# AST1080 register map
File version: 1.0
CPU: CM4 r0p1, little endian, MPU, FPU, 4 interrupt priority bits, 256 interrupts
Registers are 32-bit, read-write, reset 0x0 unless marked. A register's access mark holds for its fields unless they carry their own. Offsets are from the block's base; [hi:lo] are bit positions; {n}, {i} and the like mark numbered series.

## otp_reg
Base 0x74C07000
0x00 OTP_REG000 — otp key
  [31:0] REGOTPENABLEID ro
0x04 OTP_REG004 — otp\_cmd\_m0
  [31:0] REGOTPCMDM0
0x08 OTP_REG008 — otp\_wdata\_m0\_0
  [31:0] REGOTPWDATAM00
0x0C OTP_REG00C — otp\_wdata\_m0\_1
  [31:0] REGOTPWDATAM01
0x10 OTP_REG010 — otp\_wdata\_m0\_2
  [31:0] REGOTPWDATAM02
0x14 OTP_REG014 — otp\_wdata\_m0\_3
  [31:0] REGOTPWDATAM03
0x18 OTP_REG018 — otp\_states\_m0
  [31:0] REGOTPSTATUSM0 ro
0x1C OTP_REG01C — otp\_addr\_m0
  [15:0] REGOTPADDRM0
0x20 OTP_REG020 — otp\_rdata\_m0
  [31:0] REGOTPRDATAM0 ro
0x24 OTP_REG024 — otp\_cmd\_m1
  [31:0] REGOTPCMDM1
0x28 OTP_REG028 — otp\_wdata\_m1\_0
  [31:0] REGOTPWDATAM10
0x2C OTP_REG02C — otp\_wdata\_m1\_1
  [31:0] REGOTPWDATAM11
0x30 OTP_REG030 — otp\_wdata\_m1\_2
  [31:0] REGOTPWDATAM12
0x34 OTP_REG034 — otp\_wdata\_m1\_3
  [31:0] REGOTPWDATAM13
0x38 OTP_REG038 — otp\_states\_m1
  [31:0] REGOTPSTATUSM1 ro
0x3C OTP_REG03C — otp\_addr\_m1
  [15:0] REGOTPADDRM1
0x40 OTP_REG040 — otp\_rdata\_m1
  [31:0] REGOTPRDATAM1 ro
0x44 OTP_REG044 — otp\_cmd\_m2
  [31:0] REGOTPCMDM2
0x48 OTP_REG048 — otp\_wdata\_m2\_0
  [31:0] REGOTPWDATAM20
0x4C OTP_REG04C — otp\_wdata\_m2\_1
  [31:0] REGOTPWDATAM21
0x50 OTP_REG050 — otp\_wdata\_m2\_2
  [31:0] REGOTPWDATAM22
0x54 OTP_REG054 — otp\_wdata\_m2\_3
  [31:0] REGOTPWDATAM23
0x58 OTP_REG058 — otp\_states\_m2
  [31:0] REGOTPSTATUSM2 ro
0x5C OTP_REG05C — otp\_addr\_m2
  [15:0] REGOTPADDRM2
0x60 OTP_REG060 — otp\_rdata\_m2
  [31:0] REGOTPRDATAM2 ro
0x64 OTP_REG064 — otp\_cmd\_m3
  [31:0] REGOTPCMDM3
0x68 OTP_REG068 — otp\_wdata\_m3\_0
  [31:0] REGOTPWDATAM30
0x6C OTP_REG06C — otp\_wdata\_m3\_1
  [31:0] REGOTPWDATAM31
0x70 OTP_REG070 — otp\_wdata\_m3\_2
  [31:0] REGOTPWDATAM32
0x74 OTP_REG074 — otp\_wdata\_m3\_3
  [31:0] REGOTPWDATAM33
0x78 OTP_REG078 — otp\_states\_m3
  [31:0] REGOTPSTATUSM3 ro
0x7C OTP_REG07C — otp\_addr\_m3
  [15:0] REGOTPADDRM3
0x80 OTP_REG080 — otp\_rdata\_m3
  [31:0] REGOTPRDATAM3 ro
0x84 OTP_REG084 — otp\_cmd\_m4
  [31:0] REGOTPCMDM4
0x88 OTP_REG088 — otp\_wdata\_m4\_0
  [31:0] REGOTPWDATAM40
0x8C OTP_REG08C — otp\_wdata\_m4\_1
  [31:0] REGOTPWDATAM41
0x90 OTP_REG090 — otp\_wdata\_m4\_2
  [31:0] REGOTPWDATAM42
0x94 OTP_REG094 — otp\_wdata\_m4\_3
  [31:0] REGOTPWDATAM43
0x98 OTP_REG098 — otp\_states\_m4
  [31:0] REGOTPSTATUSM4 ro
0x9C OTP_REG09C — otp\_addr\_m4
  [15:0] REGOTPADDRM4
0xA0 OTP_REG0A0 — otp\_rdata\_m4
  [31:0] REGOTPRDATAM4 ro
0xA4 OTP_REG0A4 — otp\_cmd\_m5
  [31:0] REGOTPCMDM5
0xA8 OTP_REG0A8 — otp\_wdata\_m5\_0
  [31:0] REGOTPWDATAM50
0xAC OTP_REG0AC — otp\_wdata\_m5\_1
  [31:0] REGOTPWDATAM51
0xB0 OTP_REG0B0 — otp\_wdata\_m5\_2
  [31:0] REGOTPWDATAM52
0xB4 OTP_REG0B4 — otp\_wdata\_m5\_3
  [31:0] REGOTPWDATAM53
0xB8 OTP_REG0B8 — otp\_states\_m5
  [31:0] REGOTPSTATUSM5 ro
0xBC OTP_REG0BC — otp\_addr\_m5
  [15:0] REGOTPADDRM5
0xC0 OTP_REG0C0 — otp\_rdata\_m5
  [31:0] REGOTPRDATAM5 ro
0xC4 OTP_REG0C4 — otp\_dbg\_00
  [31:0] REGDBG0 ro
0xC8 OTP_REG0C8 — otp\_dbg\_01
  [31:0] REGDBG1 ro
0xCC OTP_REG0CC — ecc\_rlock
  [0] REGECCRLOCK
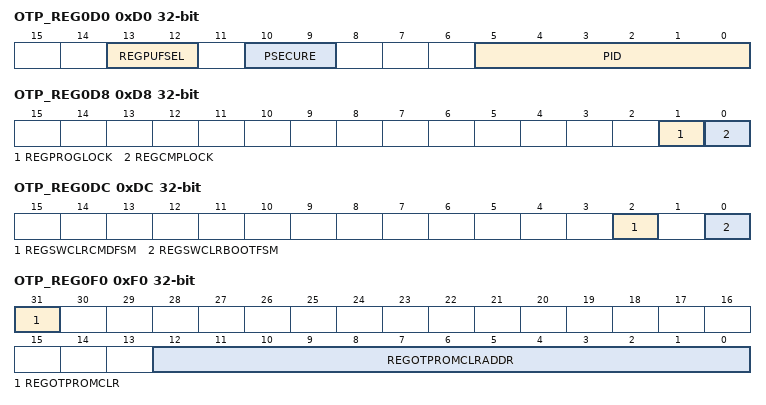
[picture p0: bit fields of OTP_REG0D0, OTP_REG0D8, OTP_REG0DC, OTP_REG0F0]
0xD0 OTP_REG0D0 — pid
  [13:12] REGPUFSEL, [10:9] PSECURE ro, [5:0] PID ro
0xD4 OTP_REG0D4 — otp\_eccbrp\_en
  [0] REGOTPECCBRPEN
0xD8 OTP_REG0D8 — OTP\_CMD\_LOCK
  [1] REGPROGLOCK, [0] REGCMPLOCK
0xDC OTP_REG0DC — otp\_sw\_reset
  [2] REGSWCLRCMDFSM, [0] REGSWCLRBOOTFSM
0xE0 OTP_REG0E0 — otp\_trng\_dbg
  [31:0] REGDBGTRNG ro
0xF0 OTP_REG0F0 — otp\_rom\_clr
  [31] REGOTPROMCLR, [12:0] REGOTPROMCLRADDR
0xF4 OTP_REG0F4 — otp\_puf\_ctrl
  [31:0] REGPUFRTCTRL
0xF8 OTP_REG0F8 — otp\_puf\_sts
  [31:0] REGPUFRTSTS ro
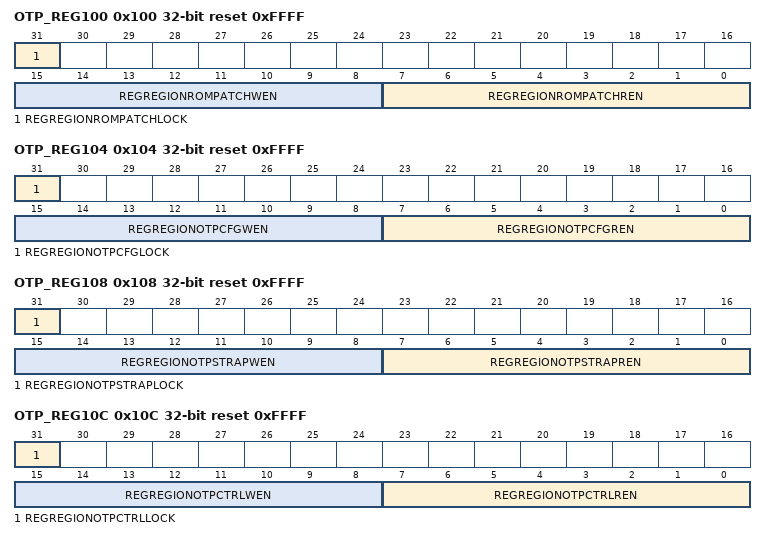
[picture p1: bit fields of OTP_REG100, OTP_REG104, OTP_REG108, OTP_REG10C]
0x100 OTP_REG100 reset 0xFFFF — OTP\_REGION\_ROM\_PATCH
  [31] REGREGIONROMPATCHLOCK, [15:8] REGREGIONROMPATCHWEN, [7:0] REGREGIONROMPATCHREN
0x104 OTP_REG104 reset 0xFFFF — OTP\_REGION\_OTPCFG
  [31] REGREGIONOTPCFGLOCK, [15:8] REGREGIONOTPCFGWEN, [7:0] REGREGIONOTPCFGREN
0x108 OTP_REG108 reset 0xFFFF — OTP\_REGION\_OTPSTRAP
  [31] REGREGIONOTPSTRAPLOCK, [15:8] REGREGIONOTPSTRAPWEN, [7:0] REGREGIONOTPSTRAPREN
0x10C OTP_REG10C reset 0xFFFF — OTP\_REGION\_OTP\_CTRL
  [31] REGREGIONOTPCTRLLOCK, [15:8] REGREGIONOTPCTRLWEN, [7:0] REGREGIONOTPCTRLREN
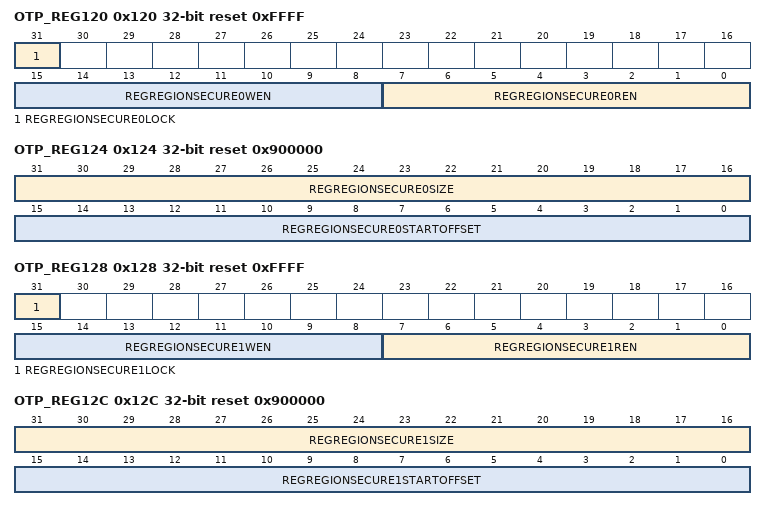
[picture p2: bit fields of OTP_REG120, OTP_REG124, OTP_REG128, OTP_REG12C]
0x120 OTP_REG120 reset 0xFFFF — OTP\_REGION\_SECURE0
  [31] REGREGIONSECURE0LOCK, [15:8] REGREGIONSECURE0WEN, [7:0] REGREGIONSECURE0REN
0x124 OTP_REG124 reset 0x900000 — OTP\_REGION\_SECURE0\_RANGE
  [31:16] REGREGIONSECURE0SIZE, [15:0] REGREGIONSECURE0STARTOFFSET
0x128 OTP_REG128 reset 0xFFFF — OTP\_REGION\_SECURE1
  [31] REGREGIONSECURE1LOCK, [15:8] REGREGIONSECURE1WEN, [7:0] REGREGIONSECURE1REN
0x12C OTP_REG12C reset 0x900000 — OTP\_REGION\_SECURE\_RANGE1
  [31:16] REGREGIONSECURE1SIZE, [15:0] REGREGIONSECURE1STARTOFFSET
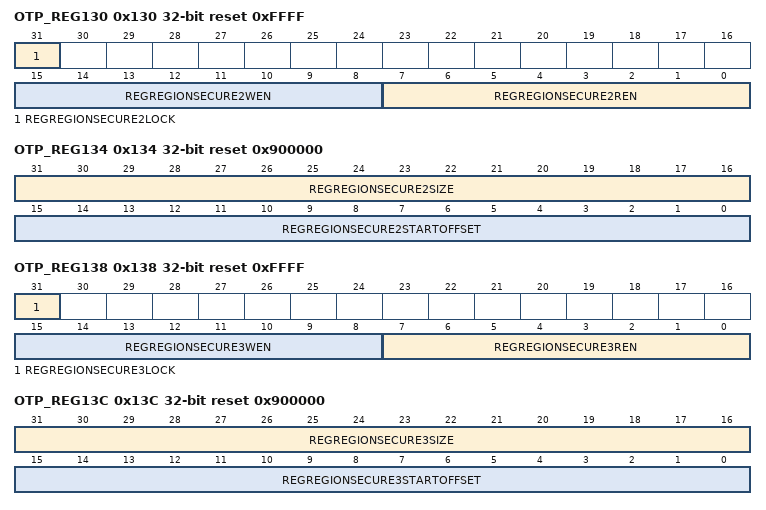
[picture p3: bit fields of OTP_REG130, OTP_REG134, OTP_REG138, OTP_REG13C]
0x130 OTP_REG130 reset 0xFFFF — OTP\_REGION\_SECURE2
  [31] REGREGIONSECURE2LOCK, [15:8] REGREGIONSECURE2WEN, [7:0] REGREGIONSECURE2REN
0x134 OTP_REG134 reset 0x900000 — OTP\_REGION\_SECURE\_RANGE2
  [31:16] REGREGIONSECURE2SIZE, [15:0] REGREGIONSECURE2STARTOFFSET
0x138 OTP_REG138 reset 0xFFFF — OTP\_REGION\_SECURE3
  [31] REGREGIONSECURE3LOCK, [15:8] REGREGIONSECURE3WEN, [7:0] REGREGIONSECURE3REN
0x13C OTP_REG13C reset 0x900000 — OTP\_REGION\_SECURE\_RANGE3
  [31:16] REGREGIONSECURE3SIZE, [15:0] REGREGIONSECURE3STARTOFFSET
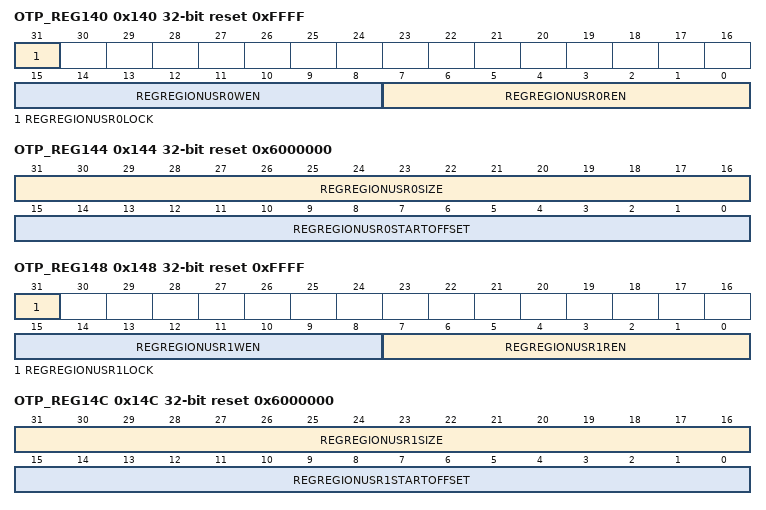
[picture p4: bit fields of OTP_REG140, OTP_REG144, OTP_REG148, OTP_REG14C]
0x140 OTP_REG140 reset 0xFFFF — OTP\_REGION\_USR\_0
  [31] REGREGIONUSR0LOCK, [15:8] REGREGIONUSR0WEN, [7:0] REGREGIONUSR0REN
0x144 OTP_REG144 reset 0x6000000 — OTP\_REGION\_USR\_0\_RANGE
  [31:16] REGREGIONUSR0SIZE, [15:0] REGREGIONUSR0STARTOFFSET
0x148 OTP_REG148 reset 0xFFFF — OTP\_REGION\_USR\_1
  [31] REGREGIONUSR1LOCK, [15:8] REGREGIONUSR1WEN, [7:0] REGREGIONUSR1REN
0x14C OTP_REG14C reset 0x6000000 — OTP\_REGION\_USR\_1\_RANGE
  [31:16] REGREGIONUSR1SIZE, [15:0] REGREGIONUSR1STARTOFFSET
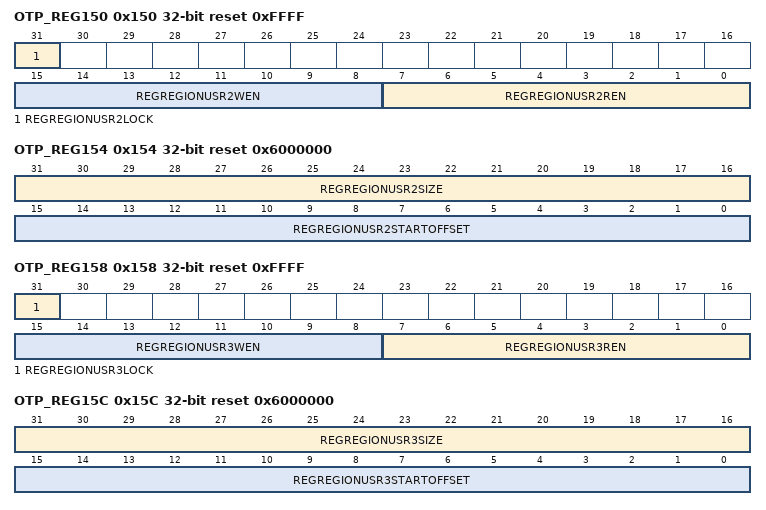
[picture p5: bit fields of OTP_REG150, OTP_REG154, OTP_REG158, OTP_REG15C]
0x150 OTP_REG150 reset 0xFFFF — OTP\_REGION\_USR\_2
  [31] REGREGIONUSR2LOCK, [15:8] REGREGIONUSR2WEN, [7:0] REGREGIONUSR2REN
0x154 OTP_REG154 reset 0x6000000 — OTP\_REGION\_USR\_2\_RANGE
  [31:16] REGREGIONUSR2SIZE, [15:0] REGREGIONUSR2STARTOFFSET
0x158 OTP_REG158 reset 0xFFFF — OTP\_REGION\_USR\_3
  [31] REGREGIONUSR3LOCK, [15:8] REGREGIONUSR3WEN, [7:0] REGREGIONUSR3REN
0x15C OTP_REG15C reset 0x6000000 — OTP\_REGION\_USR\_3\_RANGE
  [31:16] REGREGIONUSR3SIZE, [15:0] REGREGIONUSR3STARTOFFSET
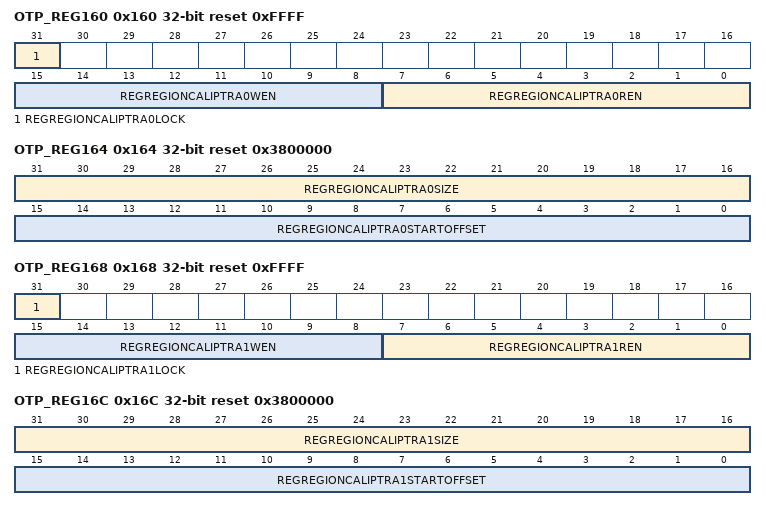
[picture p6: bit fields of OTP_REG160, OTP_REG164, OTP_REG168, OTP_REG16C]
0x160 OTP_REG160 reset 0xFFFF — OTP\_REGION\_CALIPTRA\_0
  [31] REGREGIONCALIPTRA0LOCK, [15:8] REGREGIONCALIPTRA0WEN, [7:0] REGREGIONCALIPTRA0REN
0x164 OTP_REG164 reset 0x3800000 — OTP\_REGION\_CALIPTRA\_0\_RANGE
  [31:16] REGREGIONCALIPTRA0SIZE, [15:0] REGREGIONCALIPTRA0STARTOFFSET
0x168 OTP_REG168 reset 0xFFFF — OTP\_REGION\_CALIPTRA\_1
  [31] REGREGIONCALIPTRA1LOCK, [15:8] REGREGIONCALIPTRA1WEN, [7:0] REGREGIONCALIPTRA1REN
0x16C OTP_REG16C reset 0x3800000 — OTP\_REGION\_CALIPTRA\_1\_RANGE
  [31:16] REGREGIONCALIPTRA1SIZE, [15:0] REGREGIONCALIPTRA1STARTOFFSET
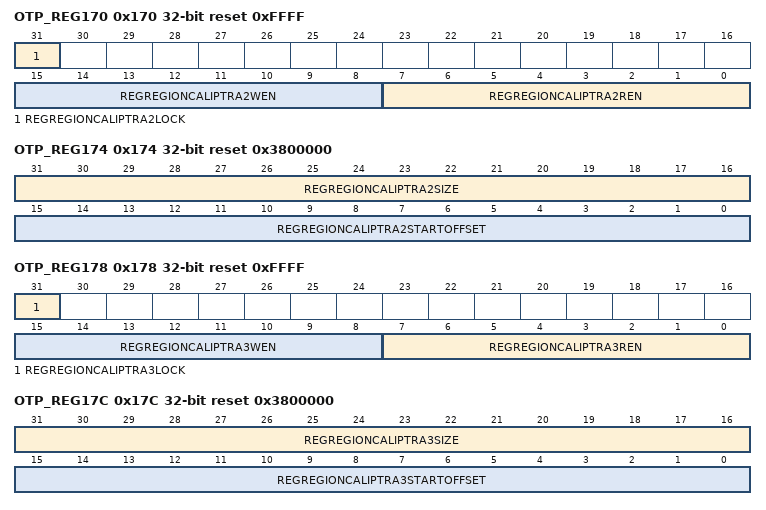
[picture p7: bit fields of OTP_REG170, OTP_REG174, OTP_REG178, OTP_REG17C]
0x170 OTP_REG170 reset 0xFFFF — OTP\_REGION\_CALIPTRA\_2
  [31] REGREGIONCALIPTRA2LOCK, [15:8] REGREGIONCALIPTRA2WEN, [7:0] REGREGIONCALIPTRA2REN
0x174 OTP_REG174 reset 0x3800000 — OTP\_REGION\_CALIPTRA\_2\_RANGE
  [31:16] REGREGIONCALIPTRA2SIZE, [15:0] REGREGIONCALIPTRA2STARTOFFSET
0x178 OTP_REG178 reset 0xFFFF — OTP\_REGION\_CALIPTRA\_3
  [31] REGREGIONCALIPTRA3LOCK, [15:8] REGREGIONCALIPTRA3WEN, [7:0] REGREGIONCALIPTRA3REN
0x17C OTP_REG17C reset 0x3800000 — OTP\_REGION\_CALIPTRA\_3\_RANGE
  [31:16] REGREGIONCALIPTRA3SIZE, [15:0] REGREGIONCALIPTRA3STARTOFFSET
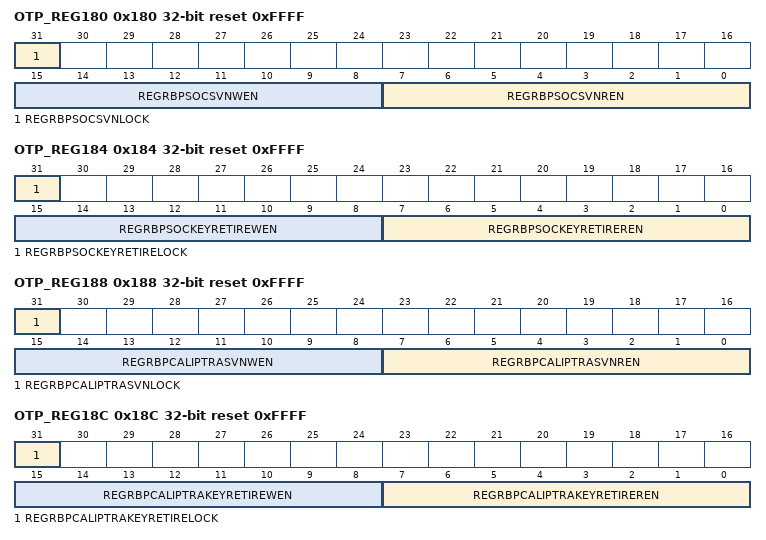
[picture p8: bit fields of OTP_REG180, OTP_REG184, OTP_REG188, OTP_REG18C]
0x180 OTP_REG180 reset 0xFFFF — OTP\_RBP\_SOC\_SVN
  [31] REGRBPSOCSVNLOCK, [15:8] REGRBPSOCSVNWEN, [7:0] REGRBPSOCSVNREN
0x184 OTP_REG184 reset 0xFFFF — OTP\_RBP\_SOC\_KEYRETIRE
  [31] REGRBPSOCKEYRETIRELOCK, [15:8] REGRBPSOCKEYRETIREWEN, [7:0] REGRBPSOCKEYRETIREREN
0x188 OTP_REG188 reset 0xFFFF — OTP\_RBP\_CALIP\_SVN
  [31] REGRBPCALIPTRASVNLOCK, [15:8] REGRBPCALIPTRASVNWEN, [7:0] REGRBPCALIPTRASVNREN
0x18C OTP_REG18C reset 0xFFFF — OTP\_RBP\_CALIP\_KEYRETIRE
  [31] REGRBPCALIPTRAKEYRETIRELOCK, [15:8] REGRBPCALIPTRAKEYRETIREWEN, [7:0] REGRBPCALIPTRAKEYRETIREREN
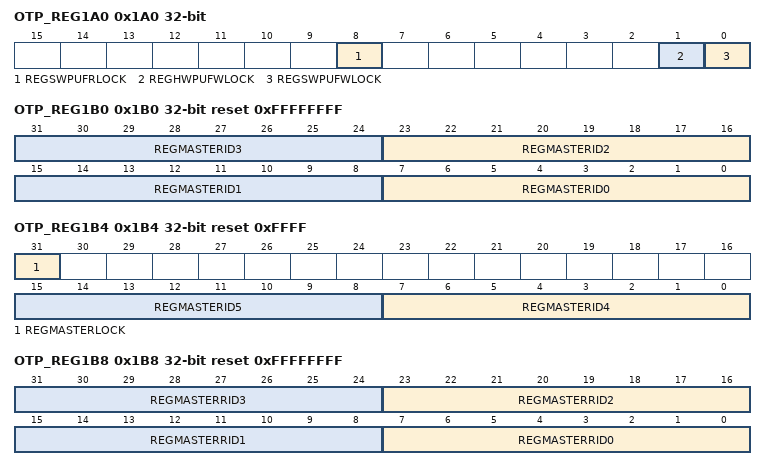
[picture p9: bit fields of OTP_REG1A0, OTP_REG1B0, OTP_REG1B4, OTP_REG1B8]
0x1A0 OTP_REG1A0 — PUF
  [8] REGSWPUFRLOCK, [1] REGHWPUFWLOCK, [0] REGSWPUFWLOCK
0x1B0 OTP_REG1B0 reset 0xFFFFFFFF — OTP\_MASTER\_ID
  [8n+7:8n] REGMASTERID{n} (n=0..3)
0x1B4 OTP_REG1B4 reset 0xFFFF — OTP\_MASTER\_ID\_EXT
  [31] REGMASTERLOCK, [15:8] REGMASTERID5, [7:0] REGMASTERID4
0x1B8 OTP_REG1B8 reset 0xFFFFFFFF — OTP\_R\_MASTER\_ID
  [8n+7:8n] REGMASTERRID{n} (n=0..3)
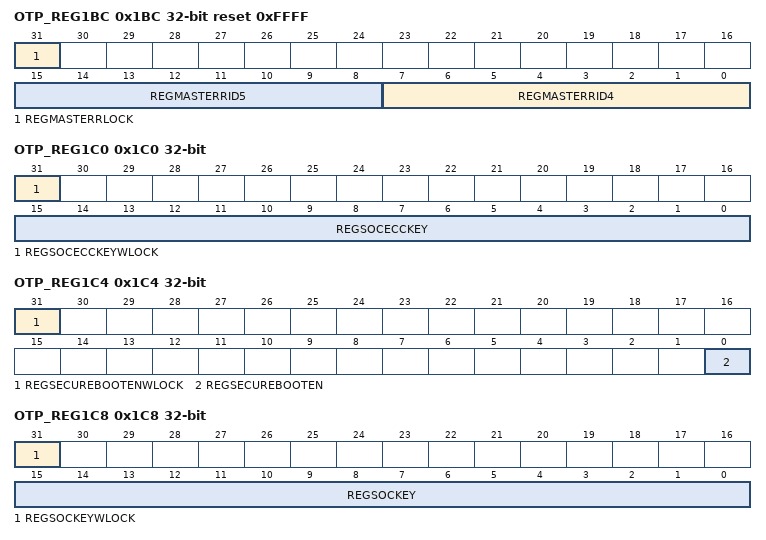
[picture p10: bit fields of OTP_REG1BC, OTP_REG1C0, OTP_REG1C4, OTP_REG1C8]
0x1BC OTP_REG1BC reset 0xFFFF — OTP\_R\_MASTER\_ID\_EXT
  [31] REGMASTERRLOCK, [15:8] REGMASTERRID5, [7:0] REGMASTERRID4
0x1C0 OTP_REG1C0 — OTP\_SOC\_ECCKEY
  [31] REGSOCECCKEYWLOCK, [15:0] REGSOCECCKEY
0x1C4 OTP_REG1C4 — OTP\_SEC\_BOOT\_EN
  [31] REGSECUREBOOTENWLOCK, [0] REGSECUREBOOTEN
0x1C8 OTP_REG1C8 — OTP\_SOC\_KEY
  [31] REGSOCKEYWLOCK, [15:0] REGSOCKEY
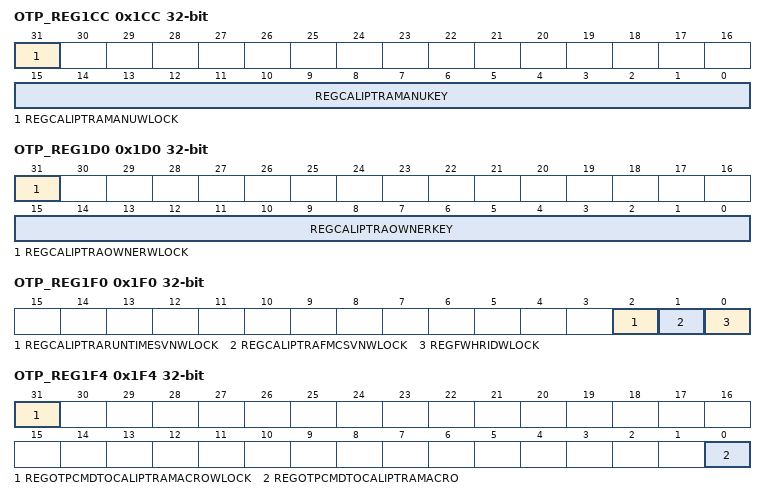
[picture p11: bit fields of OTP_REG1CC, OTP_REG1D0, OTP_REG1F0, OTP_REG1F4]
0x1CC OTP_REG1CC — OTP\_CALPITRA\_MANU\_KEY
  [31] REGCALIPTRAMANUWLOCK, [15:0] REGCALIPTRAMANUKEY
0x1D0 OTP_REG1D0 — OTP\_CALPITRA\_OWNER\_KEY
  [31] REGCALIPTRAOWNERWLOCK, [15:0] REGCALIPTRAOWNERKEY
0x1D4 OTP_REG1D4 — OTP\_FW\_ID\_LSB
  [31:0] REGFWHRIDLSB
0x1D8 OTP_REG1D8 — OTP\_FW\_ID\_MSB
  [31:0] REGFWHRIDMSB
0x1DC OTP_REG1DC — OTP\_CALIP\_FMC\_SVN
  [31:0] REGCALIPTRAFMCSVN
0x1E0 OTP_REG1E0 — OTP\_CALIP\_RUNTIME\_SVN0
  [31:0] REGCALIPTRARUNTIMESVN0
0x1E4 OTP_REG1E4 — OTP\_CALIP\_RUNTIME\_SVN1
  [31:0] REGCALIPTRARUNTIMESVN1
0x1E8 OTP_REG1E8 — OTP\_CALIP\_RUNTIME\_SVN2
  [31:0] REGCALIPTRARUNTIMESVN2
0x1EC OTP_REG1EC — OTP\_CALIP\_RUNTIME\_SVN3
  [31:0] REGCALIPTRARUNTIMESVN3
0x1F0 OTP_REG1F0 — OTP\_SVN\_WLOCK
  [2] REGCALIPTRARUNTIMESVNWLOCK, [1] REGCALIPTRAFMCSVNWLOCK, [0] REGFWHRIDWLOCK
0x1F4 OTP_REG1F4 — OTP\_CMD\_SOC2CALIP
  [31] REGOTPCMDTOCALIPTRAMACROWLOCK, [0] REGOTPCMDTOCALIPTRAMACRO
0x200 OTP_REG200 — otp\_interrupt\_en
  [31:0] REGINTREN
0x204 OTP_REG204 — otp\_interrupt\_status
  [31:0] REGINTRSTS ro
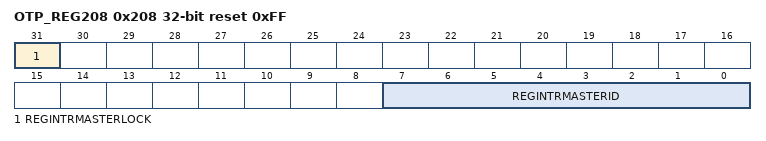
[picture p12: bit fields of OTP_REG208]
0x208 OTP_REG208 reset 0xFF — OTP\_INTR\_MID
  [31] REGINTRMASTERLOCK, [7:0] REGINTRMASTERID
0x20C OTP_REG20C — OTP\_INTR\_FUNC\_INFO
  [31:0] REGINTRINFOFUNC ro
0x210 OTP_REG210 — OTP\_INTR\_M\_INFO
  [31:0] REGINTRINFOMASTER ro
0x214 OTP_REG214 — OTP\_INTR\_R\_INFO
  [31:0] REGINTRINFOREGION ro
0x300 OTP_REG300 — OTP\_SW\_USAGE0
  [31:0] REGSWINFO0
0x304 OTP_REG304 reset 0x1 — OTP\_SW\_USAGE1
  [31:0] REGSWINFO1
0x308 OTP_REG308 reset 0x2 — OTP\_SW\_USAGE2
  [31:0] REGSWINFO2
0x30C OTP_REG30C reset 0x3 — OTP\_SW\_USAGE3
  [31:0] REGSWINFO3
0x310 OTP_REG310 reset 0x4 — OTP\_SW\_USAGE4
  [31:0] REGSWINFO4
0x314 OTP_REG314 reset 0x5 — OTP\_SW\_USAGE5
  [31:0] REGSWINFO5
0x318 OTP_REG318 reset 0x6 — OTP\_SW\_USAGE6
  [31:0] REGSWINFO6
0x31C OTP_REG31C reset 0x7 — OTP\_SW\_USAGE7
  [31:0] REGSWINFO7
0x320 OTP_REG320 reset 0x8 — OTP\_SW\_USAGE8
  [31:0] REGSWINFO8
0x324 OTP_REG324 reset 0x9 — OTP\_SW\_USAGE9
  [31:0] REGSWINFO9
0x328 OTP_REG328 reset 0x10 — OTP\_SW\_USAGE10
  [31:0] REGSWINFO10
0x32C OTP_REG32C reset 0x11 — OTP\_SW\_USAGE11
  [31:0] REGSWINFO11
